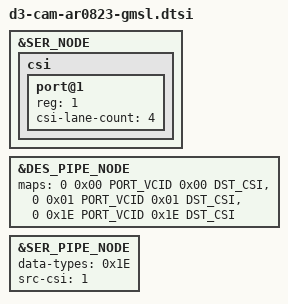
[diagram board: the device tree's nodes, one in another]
/dts-v1/;
/plugin/;

#include <d3/d3-naming-utils.dtsi>
/* cam specific */
#define CAM_MODEL ar0823
#define GMSL
#define SER_ADDR_PHYSICAL 19
#define CSI_LANES 4
/* cam specific end */

/* Carrier Board Specific */
#include <d3-hardware.dtsi>
#include <d3/cameras/d3-hardware-defines.dtsi>

/* Overlay */
#include <d3-ser-max9295-template.dtsi>
#include "d3-cam-ar0823-template.dtsi"
#include <d3/cameras/d3-overlay-cam.dtsi>

&SER_NODE {
	csi {
		port@1 {
			status = "okay";
			reg = <1>;
			csi-lane-count = <4>;
		};
	};
};

&DES_PIPE_NODE {
	status = "okay";
	//	src_vc src_dt dst_vc dst_dt dst_csi
	maps =	<0 0x00 PORT_VCID 0x00 DST_CSI>,
		<0 0x01 PORT_VCID 0x01 DST_CSI>,
		<0 0x1E PORT_VCID 0x1E DST_CSI>; /* YUV422 8-bit */
};

&SER_PIPE_NODE {
	/* Filter out metadata and manually specify data type. */
	data-types = <0x1E>;

	status = "okay";
	src-csi = <1>;
};
